VERSION ""

NS_ :

BS_: 500000

BU_: MOTOR_NODE HEADUNIT

BO_ 256 GPS_Position: 8 MOTOR_NODE
 SG_ Latitude : 0|32@1- (0.0000001,0) [-90|90] "deg" HEADUNIT
 SG_ Longitude : 32|32@1- (0.0000001,0) [-180|180] "deg" HEADUNIT

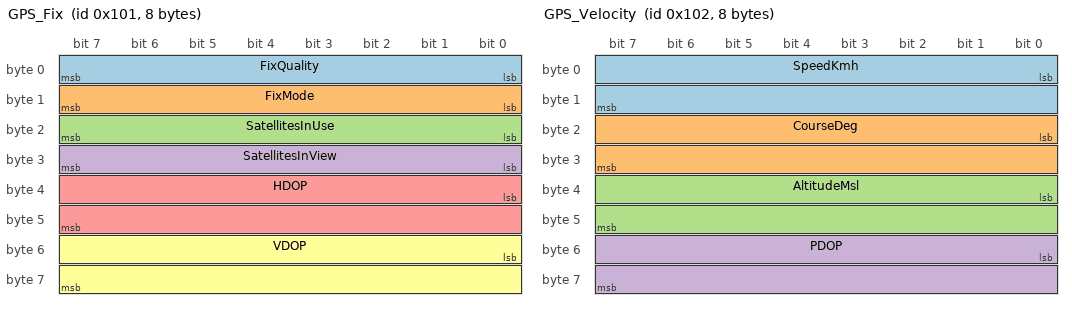
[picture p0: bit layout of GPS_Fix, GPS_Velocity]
BO_ 257 GPS_Fix: 8 MOTOR_NODE
 SG_ FixQuality : 0|8@1+ (1,0) [0|5] "" HEADUNIT
 SG_ FixMode : 8|8@1+ (1,0) [0|3] "" HEADUNIT
 SG_ SatellitesInUse : 16|8@1+ (1,0) [0|32] "" HEADUNIT
 SG_ SatellitesInView : 24|8@1+ (1,0) [0|32] "" HEADUNIT
 SG_ HDOP : 32|16@1+ (0.01,0) [0|655.35] "" HEADUNIT
 SG_ VDOP : 48|16@1+ (0.01,0) [0|655.35] "" HEADUNIT

BO_ 258 GPS_Velocity: 8 MOTOR_NODE
 SG_ SpeedKmh : 0|16@1+ (0.01,0) [0|655.35] "km/h" HEADUNIT
 SG_ CourseDeg : 16|16@1+ (0.01,0) [0|360] "deg" HEADUNIT
 SG_ AltitudeMsl : 32|16@1- (0.1,0) [-3276.8|3276.7] "m" HEADUNIT
 SG_ PDOP : 48|16@1+ (0.01,0) [0|655.35] "" HEADUNIT

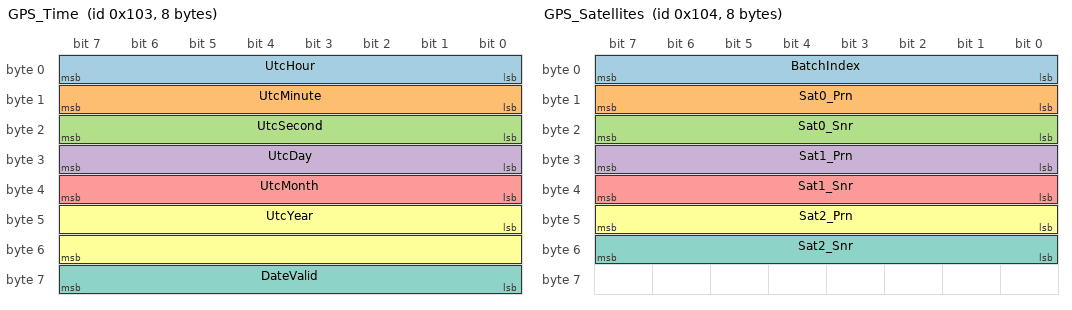
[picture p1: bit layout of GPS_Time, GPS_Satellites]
BO_ 259 GPS_Time: 8 MOTOR_NODE
 SG_ UtcHour : 0|8@1+ (1,0) [0|23] "h" HEADUNIT
 SG_ UtcMinute : 8|8@1+ (1,0) [0|59] "min" HEADUNIT
 SG_ UtcSecond : 16|8@1+ (1,0) [0|59] "s" HEADUNIT
 SG_ UtcDay : 24|8@1+ (1,0) [0|31] "" HEADUNIT
 SG_ UtcMonth : 32|8@1+ (1,0) [0|12] "" HEADUNIT
 SG_ UtcYear : 40|16@1+ (1,0) [0|65535] "" HEADUNIT
 SG_ DateValid : 56|8@1+ (1,0) [0|1] "" HEADUNIT

BO_ 260 GPS_Satellites: 8 MOTOR_NODE
 SG_ BatchIndex : 0|8@1+ (1,0) [0|10] "" HEADUNIT
 SG_ Sat0_Prn : 8|8@1+ (1,0) [0|200] "" HEADUNIT
 SG_ Sat0_Snr : 16|8@1+ (1,0) [0|99] "dBHz" HEADUNIT
 SG_ Sat1_Prn : 24|8@1+ (1,0) [0|200] "" HEADUNIT
 SG_ Sat1_Snr : 32|8@1+ (1,0) [0|99] "dBHz" HEADUNIT
 SG_ Sat2_Prn : 40|8@1+ (1,0) [0|200] "" HEADUNIT
 SG_ Sat2_Snr : 48|8@1+ (1,0) [0|99] "dBHz" HEADUNIT

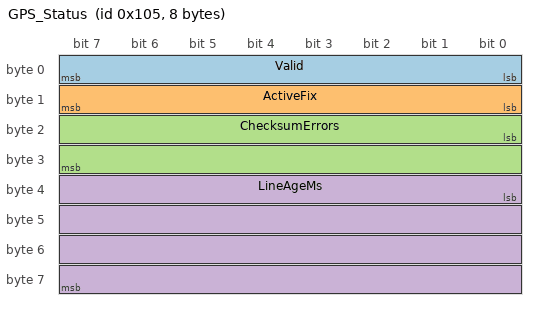
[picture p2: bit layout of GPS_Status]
BO_ 261 GPS_Status: 8 MOTOR_NODE
 SG_ Valid : 0|8@1+ (1,0) [0|1] "" HEADUNIT
 SG_ ActiveFix : 8|8@1+ (1,0) [0|1] "" HEADUNIT
 SG_ ChecksumErrors : 16|16@1+ (1,0) [0|65535] "" HEADUNIT
 SG_ LineAgeMs : 32|32@1+ (1,0) [0|4294967295] "ms" HEADUNIT

CM_ BO_ 256 "GPS position (WGS84). Intel byte order, signed 1e-7 deg fixed point.";
CM_ BO_ 257 "GPS fix quality/mode + satellite counts + horizontal/vertical dilution of precision.";
CM_ BO_ 258 "Ground speed, course over ground, altitude MSL, positional dilution of precision.";
CM_ BO_ 259 "UTC date/time as decoded from GxRMC/GxZDA. DateValid=1 once a full date has been seen.";
CM_ BO_ 260 "Per-satellite SNR table (from GxGSV), 3 satellites packed per 8-byte frame due to CAN frame size; BatchIndex selects which group of 3 is carried. Multiple frames are sent back-to-back per GPS_Satellites cycle to cover all satellites in view. Elevation/azimuth are not carried on the bus (full detail remains available via the motor-node web UI) to keep the frame compact.";
CM_ BO_ 261 "Overall GPS receiver health: Valid=have we ever parsed a complete checksummed sentence, ActiveFix=RMC status A, ChecksumErrors=running NMEA checksum failure counter, LineAgeMs=milliseconds since the last valid NMEA sentence (bus-side freshness watchdog).";

BA_DEF_ BO_ "GenMsgCycleTime" INT 0 0 60000;
BA_DEF_DEF_ "GenMsgCycleTime" 0;
BA_ "GenMsgCycleTime" BO_ 256 2000;
BA_ "GenMsgCycleTime" BO_ 257 2000;
BA_ "GenMsgCycleTime" BO_ 258 2000;
BA_ "GenMsgCycleTime" BO_ 259 30000;
BA_ "GenMsgCycleTime" BO_ 260 5000;
BA_ "GenMsgCycleTime" BO_ 261 5000;
